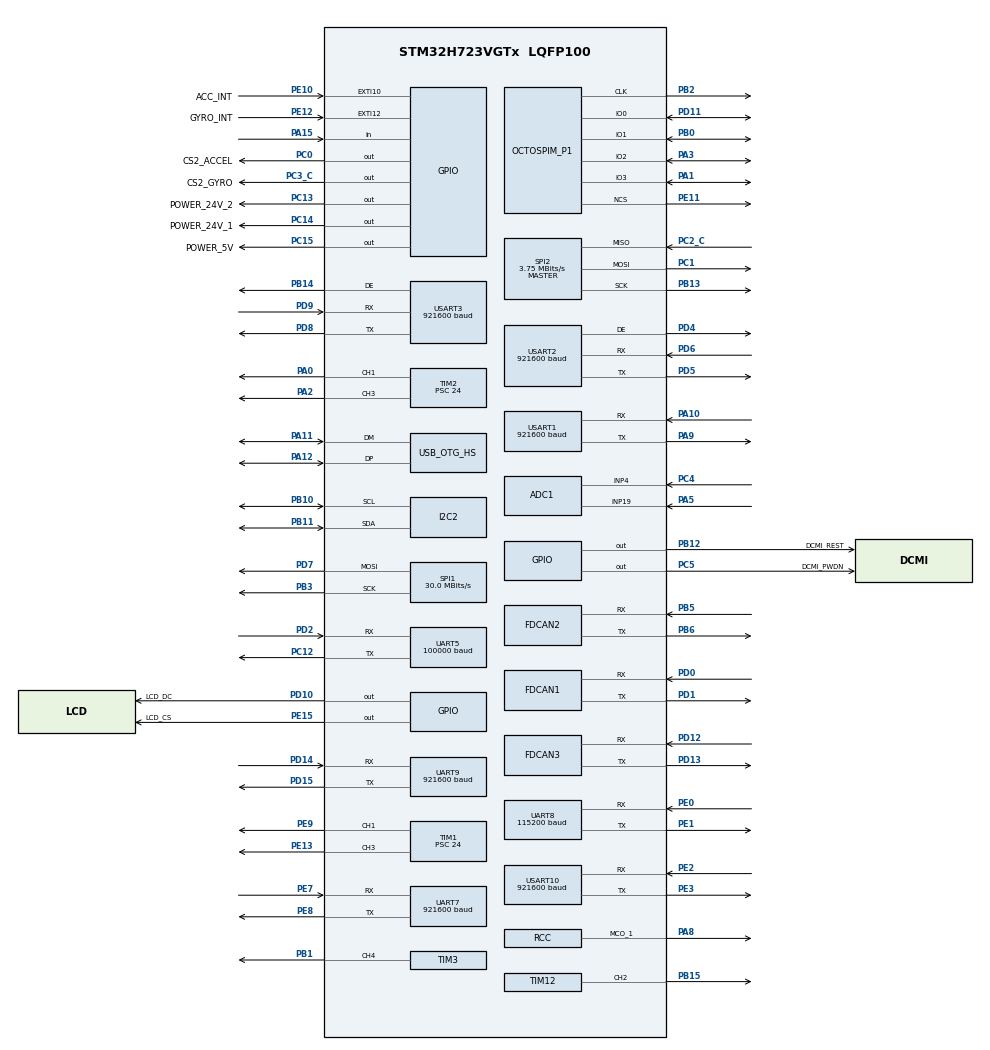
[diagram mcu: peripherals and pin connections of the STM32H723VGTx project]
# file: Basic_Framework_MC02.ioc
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ADC1.Channel-0\#ChannelRegularConversion=ADC_CHANNEL_4
ADC1.Channel-1\#ChannelRegularConversion=ADC_CHANNEL_19
ADC1.ClockPrescaler=ADC_CLOCK_ASYNC_DIV64
ADC1.ContinuousConvMode=ENABLE
ADC1.ConversionDataManagement=ADC_CONVERSIONDATA_DMA_CIRCULAR
ADC1.NbrOfConversion=2
ADC1.NbrOfConversionFlag=1
ADC1.OffsetNumber-0\#ChannelRegularConversion=ADC_OFFSET_NONE
ADC1.OffsetNumber-1\#ChannelRegularConversion=ADC_OFFSET_NONE
ADC1.OffsetSignedSaturation-0\#ChannelRegularConversion=DISABLE
ADC1.OffsetSignedSaturation-1\#ChannelRegularConversion=DISABLE
ADC1.Rank-0\#ChannelRegularConversion=1
ADC1.Rank-1\#ChannelRegularConversion=2
ADC1.SamplingTime-0\#ChannelRegularConversion=ADC_SAMPLETIME_32CYCLES_5
ADC1.SamplingTime-1\#ChannelRegularConversion=ADC_SAMPLETIME_32CYCLES_5
ADC1.master=1
CORTEX_M7.BaseAddress-Cortex_Memory_Protection_Unit_Region0_Settings=0x24000000
CORTEX_M7.CPU_DCache=Disabled
CORTEX_M7.CPU_ICache=Disabled
CORTEX_M7.Enable-Cortex_Memory_Protection_Unit_Region0_Settings=MPU_REGION_ENABLE
CORTEX_M7.IsBufferable-Cortex_Memory_Protection_Unit_Region0_Settings=MPU_ACCESS_BUFFERABLE
CORTEX_M7.IsCacheable-Cortex_Memory_Protection_Unit_Region0_Settings=MPU_ACCESS_CACHEABLE
CORTEX_M7.MPU_Control=__NULL
CORTEX_M7.Size-Cortex_Memory_Protection_Unit_Region0_Settings=MPU_REGION_SIZE_512B
CORTEX_M7.TypeExtField-Cortex_Memory_Protection_Unit_Region0_Settings=MPU_TEX_LEVEL1
Dma.ADC1.0.Direction=DMA_PERIPH_TO_MEMORY
Dma.ADC1.0.EventEnable=DISABLE
Dma.ADC1.0.FIFOMode=DMA_FIFOMODE_DISABLE
Dma.ADC1.0.Instance=DMA1_Stream0
Dma.ADC1.0.MemDataAlignment=DMA_MDATAALIGN_HALFWORD
Dma.ADC1.0.MemInc=DMA_MINC_ENABLE
Dma.ADC1.0.Mode=DMA_CIRCULAR
Dma.ADC1.0.PeriphDataAlignment=DMA_PDATAALIGN_HALFWORD
Dma.ADC1.0.PeriphInc=DMA_PINC_DISABLE
Dma.ADC1.0.Polarity=HAL_DMAMUX_REQ_GEN_RISING
Dma.ADC1.0.Priority=DMA_PRIORITY_LOW
Dma.ADC1.0.RequestNumber=1
Dma.ADC1.0.SignalID=NONE
Dma.ADC1.0.SyncEnable=DISABLE
Dma.ADC1.0.SyncPolarity=HAL_DMAMUX_SYNC_NO_EVENT
Dma.ADC1.0.SyncRequestNumber=1
Dma.ADC1.0.SyncSignalID=NONE
Dma.I2C2_RX.1.Direction=DMA_PERIPH_TO_MEMORY
Dma.I2C2_RX.1.EventEnable=DISABLE
Dma.I2C2_RX.1.FIFOMode=DMA_FIFOMODE_DISABLE
Dma.I2C2_RX.1.Instance=DMA1_Stream2
Dma.I2C2_RX.1.MemDataAlignment=DMA_MDATAALIGN_BYTE
Dma.I2C2_RX.1.MemInc=DMA_MINC_ENABLE
Dma.I2C2_RX.1.Mode=DMA_NORMAL
Dma.I2C2_RX.1.PeriphDataAlignment=DMA_PDATAALIGN_BYTE
Dma.I2C2_RX.1.PeriphInc=DMA_PINC_DISABLE
Dma.I2C2_RX.1.Polarity=HAL_DMAMUX_REQ_GEN_RISING
Dma.I2C2_RX.1.Priority=DMA_PRIORITY_LOW
Dma.I2C2_RX.1.RequestNumber=1
Dma.I2C2_RX.1.SignalID=NONE
Dma.I2C2_RX.1.SyncEnable=DISABLE
Dma.I2C2_RX.1.SyncPolarity=HAL_DMAMUX_SYNC_NO_EVENT
Dma.I2C2_RX.1.SyncRequestNumber=1
Dma.I2C2_RX.1.SyncSignalID=NONE
Dma.I2C2_TX.2.Direction=DMA_MEMORY_TO_PERIPH
Dma.I2C2_TX.2.EventEnable=DISABLE
Dma.I2C2_TX.2.FIFOMode=DMA_FIFOMODE_DISABLE
Dma.I2C2_TX.2.Instance=DMA1_Stream3
Dma.I2C2_TX.2.MemDataAlignment=DMA_MDATAALIGN_BYTE
Dma.I2C2_TX.2.MemInc=DMA_MINC_ENABLE
Dma.I2C2_TX.2.Mode=DMA_NORMAL
Dma.I2C2_TX.2.PeriphDataAlignment=DMA_PDATAALIGN_BYTE
Dma.I2C2_TX.2.PeriphInc=DMA_PINC_DISABLE
Dma.I2C2_TX.2.Polarity=HAL_DMAMUX_REQ_GEN_RISING
Dma.I2C2_TX.2.Priority=DMA_PRIORITY_LOW
Dma.I2C2_TX.2.RequestNumber=1
Dma.I2C2_TX.2.SignalID=NONE
Dma.I2C2_TX.2.SyncEnable=DISABLE
Dma.I2C2_TX.2.SyncPolarity=HAL_DMAMUX_SYNC_NO_EVENT
Dma.I2C2_TX.2.SyncRequestNumber=1
Dma.I2C2_TX.2.SyncSignalID=NONE
Dma.Request0=ADC1
Dma.Request1=I2C2_RX
Dma.Request10=USART10_TX
Dma.Request11=UART7_RX
Dma.Request12=UART7_TX
Dma.Request13=UART5_RX
Dma.Request14=UART8_RX
Dma.Request15=UART8_TX
Dma.Request2=I2C2_TX
Dma.Request3=UART9_RX
Dma.Request4=UART9_TX
Dma.Request5=USART3_RX
Dma.Request6=USART3_TX
Dma.Request7=USART1_TX
Dma.Request8=USART1_RX
Dma.Request9=USART10_RX
Dma.UART5_RX.13.Direction=DMA_PERIPH_TO_MEMORY
Dma.UART5_RX.13.EventEnable=DISABLE
Dma.UART5_RX.13.FIFOMode=DMA_FIFOMODE_DISABLE
Dma.UART5_RX.13.Instance=DMA1_Stream7
Dma.UART5_RX.13.MemDataAlignment=DMA_MDATAALIGN_BYTE
Dma.UART5_RX.13.MemInc=DMA_MINC_ENABLE
Dma.UART5_RX.13.Mode=DMA_NORMAL
Dma.UART5_RX.13.PeriphDataAlignment=DMA_PDATAALIGN_BYTE
Dma.UART5_RX.13.PeriphInc=DMA_PINC_DISABLE
Dma.UART5_RX.13.Polarity=HAL_DMAMUX_REQ_GEN_RISING
Dma.UART5_RX.13.Priority=DMA_PRIORITY_VERY_HIGH
Dma.UART5_RX.13.RequestNumber=1
Dma.UART5_RX.13.SignalID=NONE
Dma.UART5_RX.13.SyncEnable=DISABLE
Dma.UART5_RX.13.SyncPolarity=HAL_DMAMUX_SYNC_NO_EVENT
Dma.UART5_RX.13.SyncRequestNumber=1
Dma.UART5_RX.13.SyncSignalID=NONE
Dma.UART7_RX.11.Direction=DMA_PERIPH_TO_MEMORY
Dma.UART7_RX.11.EventEnable=DISABLE
Dma.UART7_RX.11.FIFOMode=DMA_FIFOMODE_DISABLE
Dma.UART7_RX.11.Instance=DMA2_Stream0
Dma.UART7_RX.11.MemDataAlignment=DMA_MDATAALIGN_BYTE
Dma.UART7_RX.11.MemInc=DMA_MINC_ENABLE
Dma.UART7_RX.11.Mode=DMA_NORMAL
Dma.UART7_RX.11.PeriphDataAlignment=DMA_PDATAALIGN_BYTE
Dma.UART7_RX.11.PeriphInc=DMA_PINC_DISABLE
Dma.UART7_RX.11.Polarity=HAL_DMAMUX_REQ_GEN_RISING
Dma.UART7_RX.11.Priority=DMA_PRIORITY_LOW
Dma.UART7_RX.11.RequestNumber=1
Dma.UART7_RX.11.SignalID=NONE
Dma.UART7_RX.11.SyncEnable=DISABLE
Dma.UART7_RX.11.SyncPolarity=HAL_DMAMUX_SYNC_NO_EVENT
Dma.UART7_RX.11.SyncRequestNumber=1
Dma.UART7_RX.11.SyncSignalID=NONE
Dma.UART7_TX.12.Direction=DMA_MEMORY_TO_PERIPH
Dma.UART7_TX.12.EventEnable=DISABLE
Dma.UART7_TX.12.FIFOMode=DMA_FIFOMODE_DISABLE
Dma.UART7_TX.12.Instance=DMA2_Stream1
Dma.UART7_TX.12.MemDataAlignment=DMA_MDATAALIGN_BYTE
Dma.UART7_TX.12.MemInc=DMA_MINC_ENABLE
Dma.UART7_TX.12.Mode=DMA_NORMAL
Dma.UART7_TX.12.PeriphDataAlignment=DMA_PDATAALIGN_BYTE
Dma.UART7_TX.12.PeriphInc=DMA_PINC_DISABLE
Dma.UART7_TX.12.Polarity=HAL_DMAMUX_REQ_GEN_RISING
Dma.UART7_TX.12.Priority=DMA_PRIORITY_LOW
Dma.UART7_TX.12.RequestNumber=1
Dma.UART7_TX.12.SignalID=NONE
Dma.UART7_TX.12.SyncEnable=DISABLE
Dma.UART7_TX.12.SyncPolarity=HAL_DMAMUX_SYNC_NO_EVENT
Dma.UART7_TX.12.SyncRequestNumber=1
Dma.UART7_TX.12.SyncSignalID=NONE
Dma.UART8_RX.14.Direction=DMA_PERIPH_TO_MEMORY
Dma.UART8_RX.14.EventEnable=DISABLE
Dma.UART8_RX.14.FIFOMode=DMA_FIFOMODE_DISABLE
Dma.UART8_RX.14.Instance=DMA2_Stream6
Dma.UART8_RX.14.MemDataAlignment=DMA_MDATAALIGN_BYTE
Dma.UART8_RX.14.MemInc=DMA_MINC_ENABLE
Dma.UART8_RX.14.Mode=DMA_NORMAL
Dma.UART8_RX.14.PeriphDataAlignment=DMA_PDATAALIGN_BYTE
Dma.UART8_RX.14.PeriphInc=DMA_PINC_DISABLE
Dma.UART8_RX.14.Polarity=HAL_DMAMUX_REQ_GEN_RISING
Dma.UART8_RX.14.Priority=DMA_PRIORITY_LOW
Dma.UART8_RX.14.RequestNumber=1
Dma.UART8_RX.14.SignalID=NONE
Dma.UART8_RX.14.SyncEnable=DISABLE
Dma.UART8_RX.14.SyncPolarity=HAL_DMAMUX_SYNC_NO_EVENT
Dma.UART8_RX.14.SyncRequestNumber=1
Dma.UART8_RX.14.SyncSignalID=NONE
Dma.UART8_TX.15.Direction=DMA_MEMORY_TO_PERIPH
Dma.UART8_TX.15.EventEnable=DISABLE
Dma.UART8_TX.15.FIFOMode=DMA_FIFOMODE_DISABLE
Dma.UART8_TX.15.Instance=DMA2_Stream7
Dma.UART8_TX.15.MemDataAlignment=DMA_MDATAALIGN_BYTE
Dma.UART8_TX.15.MemInc=DMA_MINC_ENABLE
Dma.UART8_TX.15.Mode=DMA_NORMAL
Dma.UART8_TX.15.PeriphDataAlignment=DMA_PDATAALIGN_BYTE
Dma.UART8_TX.15.PeriphInc=DMA_PINC_DISABLE
Dma.UART8_TX.15.Polarity=HAL_DMAMUX_REQ_GEN_RISING
Dma.UART8_TX.15.Priority=DMA_PRIORITY_LOW
Dma.UART8_TX.15.RequestNumber=1
Dma.UART8_TX.15.SignalID=NONE
Dma.UART8_TX.15.SyncEnable=DISABLE
Dma.UART8_TX.15.SyncPolarity=HAL_DMAMUX_SYNC_NO_EVENT
Dma.UART8_TX.15.SyncRequestNumber=1
Dma.UART8_TX.15.SyncSignalID=NONE
Dma.UART9_RX.3.Direction=DMA_PERIPH_TO_MEMORY
Dma.UART9_RX.3.EventEnable=DISABLE
Dma.UART9_RX.3.FIFOMode=DMA_FIFOMODE_DISABLE
Dma.UART9_RX.3.Instance=DMA1_Stream4
Dma.UART9_RX.3.MemDataAlignment=DMA_MDATAALIGN_BYTE
Dma.UART9_RX.3.MemInc=DMA_MINC_ENABLE
Dma.UART9_RX.3.Mode=DMA_NORMAL
Dma.UART9_RX.3.PeriphDataAlignment=DMA_PDATAALIGN_BYTE
Dma.UART9_RX.3.PeriphInc=DMA_PINC_DISABLE
Dma.UART9_RX.3.Polarity=HAL_DMAMUX_REQ_GEN_RISING
Dma.UART9_RX.3.Priority=DMA_PRIORITY_HIGH
Dma.UART9_RX.3.RequestNumber=1
Dma.UART9_RX.3.SignalID=NONE
Dma.UART9_RX.3.SyncEnable=DISABLE
Dma.UART9_RX.3.SyncPolarity=HAL_DMAMUX_SYNC_NO_EVENT
Dma.UART9_RX.3.SyncRequestNumber=1
Dma.UART9_RX.3.SyncSignalID=NONE
Dma.UART9_TX.4.Direction=DMA_MEMORY_TO_PERIPH
Dma.UART9_TX.4.EventEnable=DISABLE
Dma.UART9_TX.4.FIFOMode=DMA_FIFOMODE_DISABLE
Dma.UART9_TX.4.Instance=DMA1_Stream5
Dma.UART9_TX.4.MemDataAlignment=DMA_MDATAALIGN_BYTE
Dma.UART9_TX.4.MemInc=DMA_MINC_ENABLE
Dma.UART9_TX.4.Mode=DMA_NORMAL
Dma.UART9_TX.4.PeriphDataAlignment=DMA_PDATAALIGN_BYTE
Dma.UART9_TX.4.PeriphInc=DMA_PINC_DISABLE
Dma.UART9_TX.4.Polarity=HAL_DMAMUX_REQ_GEN_RISING
Dma.UART9_TX.4.Priority=DMA_PRIORITY_HIGH
Dma.UART9_TX.4.RequestNumber=1
Dma.UART9_TX.4.SignalID=NONE
Dma.UART9_TX.4.SyncEnable=DISABLE
Dma.UART9_TX.4.SyncPolarity=HAL_DMAMUX_SYNC_NO_EVENT
Dma.UART9_TX.4.SyncRequestNumber=1
Dma.UART9_TX.4.SyncSignalID=NONE
Dma.USART10_RX.9.Direction=DMA_PERIPH_TO_MEMORY
Dma.USART10_RX.9.EventEnable=DISABLE
Dma.USART10_RX.9.FIFOMode=DMA_FIFOMODE_DISABLE
Dma.USART10_RX.9.Instance=DMA2_Stream4
Dma.USART10_RX.9.MemDataAlignment=DMA_MDATAALIGN_BYTE
Dma.USART10_RX.9.MemInc=DMA_MINC_ENABLE
Dma.USART10_RX.9.Mode=DMA_NORMAL
Dma.USART10_RX.9.PeriphDataAlignment=DMA_PDATAALIGN_BYTE
Dma.USART10_RX.9.PeriphInc=DMA_PINC_DISABLE
Dma.USART10_RX.9.Polarity=HAL_DMAMUX_REQ_GEN_RISING
Dma.USART10_RX.9.Priority=DMA_PRIORITY_LOW
Dma.USART10_RX.9.RequestNumber=1
Dma.USART10_RX.9.SignalID=NONE
Dma.USART10_RX.9.SyncEnable=DISABLE
Dma.USART10_RX.9.SyncPolarity=HAL_DMAMUX_SYNC_NO_EVENT
Dma.USART10_RX.9.SyncRequestNumber=1
Dma.USART10_RX.9.SyncSignalID=NONE
Dma.USART10_TX.10.Direction=DMA_MEMORY_TO_PERIPH
Dma.USART10_TX.10.EventEnable=DISABLE
Dma.USART10_TX.10.FIFOMode=DMA_FIFOMODE_DISABLE
Dma.USART10_TX.10.Instance=DMA2_Stream5
Dma.USART10_TX.10.MemDataAlignment=DMA_MDATAALIGN_BYTE
Dma.USART10_TX.10.MemInc=DMA_MINC_ENABLE
Dma.USART10_TX.10.Mode=DMA_NORMAL
Dma.USART10_TX.10.PeriphDataAlignment=DMA_PDATAALIGN_BYTE
Dma.USART10_TX.10.PeriphInc=DMA_PINC_DISABLE
Dma.USART10_TX.10.Polarity=HAL_DMAMUX_REQ_GEN_RISING
Dma.USART10_TX.10.Priority=DMA_PRIORITY_LOW
Dma.USART10_TX.10.RequestNumber=1
Dma.USART10_TX.10.SignalID=NONE
Dma.USART10_TX.10.SyncEnable=DISABLE
Dma.USART10_TX.10.SyncPolarity=HAL_DMAMUX_SYNC_NO_EVENT
Dma.USART10_TX.10.SyncRequestNumber=1
Dma.USART10_TX.10.SyncSignalID=NONE
Dma.USART1_RX.8.Direction=DMA_PERIPH_TO_MEMORY
Dma.USART1_RX.8.EventEnable=DISABLE
Dma.USART1_RX.8.FIFOMode=DMA_FIFOMODE_DISABLE
Dma.USART1_RX.8.Instance=DMA2_Stream3
Dma.USART1_RX.8.MemDataAlignment=DMA_MDATAALIGN_BYTE
Dma.USART1_RX.8.MemInc=DMA_MINC_ENABLE
Dma.USART1_RX.8.Mode=DMA_NORMAL
Dma.USART1_RX.8.PeriphDataAlignment=DMA_PDATAALIGN_BYTE
Dma.USART1_RX.8.PeriphInc=DMA_PINC_DISABLE
Dma.USART1_RX.8.Polarity=HAL_DMAMUX_REQ_GEN_RISING
Dma.USART1_RX.8.Priority=DMA_PRIORITY_LOW
Dma.USART1_RX.8.RequestNumber=1
Dma.USART1_RX.8.SignalID=NONE
Dma.USART1_RX.8.SyncEnable=DISABLE
Dma.USART1_RX.8.SyncPolarity=HAL_DMAMUX_SYNC_NO_EVENT
Dma.USART1_RX.8.SyncRequestNumber=1
Dma.USART1_RX.8.SyncSignalID=NONE
Dma.USART1_TX.7.Direction=DMA_MEMORY_TO_PERIPH
Dma.USART1_TX.7.EventEnable=DISABLE
Dma.USART1_TX.7.FIFOMode=DMA_FIFOMODE_DISABLE
Dma.USART1_TX.7.Instance=DMA2_Stream2
Dma.USART1_TX.7.MemDataAlignment=DMA_MDATAALIGN_BYTE
Dma.USART1_TX.7.MemInc=DMA_MINC_ENABLE
Dma.USART1_TX.7.Mode=DMA_NORMAL
Dma.USART1_TX.7.PeriphDataAlignment=DMA_PDATAALIGN_BYTE
Dma.USART1_TX.7.PeriphInc=DMA_PINC_DISABLE
Dma.USART1_TX.7.Polarity=HAL_DMAMUX_REQ_GEN_RISING
Dma.USART1_TX.7.Priority=DMA_PRIORITY_LOW
Dma.USART1_TX.7.RequestNumber=1
Dma.USART1_TX.7.SignalID=NONE
Dma.USART1_TX.7.SyncEnable=DISABLE
Dma.USART1_TX.7.SyncPolarity=HAL_DMAMUX_SYNC_NO_EVENT
Dma.USART1_TX.7.SyncRequestNumber=1
Dma.USART1_TX.7.SyncSignalID=NONE
Dma.USART3_RX.5.Direction=DMA_PERIPH_TO_MEMORY
Dma.USART3_RX.5.EventEnable=DISABLE
Dma.USART3_RX.5.FIFOMode=DMA_FIFOMODE_DISABLE
Dma.USART3_RX.5.Instance=DMA1_Stream6
Dma.USART3_RX.5.MemDataAlignment=DMA_MDATAALIGN_BYTE
Dma.USART3_RX.5.MemInc=DMA_MINC_ENABLE
Dma.USART3_RX.5.Mode=DMA_NORMAL
Dma.USART3_RX.5.PeriphDataAlignment=DMA_PDATAALIGN_BYTE
Dma.USART3_RX.5.PeriphInc=DMA_PINC_DISABLE
Dma.USART3_RX.5.Polarity=HAL_DMAMUX_REQ_GEN_RISING
Dma.USART3_RX.5.Priority=DMA_PRIORITY_LOW
Dma.USART3_RX.5.RequestNumber=1
Dma.USART3_RX.5.SignalID=NONE
Dma.USART3_RX.5.SyncEnable=DISABLE
Dma.USART3_RX.5.SyncPolarity=HAL_DMAMUX_SYNC_NO_EVENT
Dma.USART3_RX.5.SyncRequestNumber=1
Dma.USART3_RX.5.SyncSignalID=NONE
Dma.USART3_TX.6.Direction=DMA_MEMORY_TO_PERIPH
Dma.USART3_TX.6.EventEnable=DISABLE
Dma.USART3_TX.6.FIFOMode=DMA_FIFOMODE_DISABLE
Dma.USART3_TX.6.Instance=DMA1_Stream1
Dma.USART3_TX.6.MemDataAlignment=DMA_MDATAALIGN_BYTE
Dma.USART3_TX.6.MemInc=DMA_MINC_ENABLE
Dma.USART3_TX.6.Mode=DMA_NORMAL
Dma.USART3_TX.6.PeriphDataAlignment=DMA_PDATAALIGN_BYTE
Dma.USART3_TX.6.PeriphInc=DMA_PINC_DISABLE
Dma.USART3_TX.6.Polarity=HAL_DMAMUX_REQ_GEN_RISING
Dma.USART3_TX.6.Priority=DMA_PRIORITY_LOW
Dma.USART3_TX.6.RequestNumber=1
Dma.USART3_TX.6.SignalID=NONE
Dma.USART3_TX.6.SyncEnable=DISABLE
Dma.USART3_TX.6.SyncPolarity=HAL_DMAMUX_SYNC_NO_EVENT
Dma.USART3_TX.6.SyncRequestNumber=1
Dma.USART3_TX.6.SyncSignalID=NONE
FDCAN1.CalculateBaudRateNominal=1000000
FDCAN1.CalculateTimeBitNominal=1000
FDCAN1.CalculateTimeQuantumNominal=25.0
FDCAN1.DataPrescaler=3
FDCAN1.DataSyncJumpWidth=10
FDCAN1.DataTimeSeg1=29
FDCAN1.DataTimeSeg2=10
FDCAN1.NominalPrescaler=3
FDCAN1.NominalTimeSeg1=29
FDCAN1.NominalTimeSeg2=10
FDCAN1.ProtocolException=ENABLE
FDCAN1.RxFifo0ElmtsNbr=4
FDCAN1.RxFifo1ElmtsNbr=4
FDCAN1.StdFiltersNbr=14
FDCAN1.TxFifoQueueElmtsNbr=4
FDCAN2.CalculateBaudRateNominal=1000000
FDCAN2.CalculateTimeBitNominal=1000
FDCAN2.CalculateTimeQuantumNominal=25.0
FDCAN2.DataPrescaler=3
FDCAN2.DataSyncJumpWidth=10
FDCAN2.DataTimeSeg1=29
FDCAN2.DataTimeSeg2=10
FDCAN2.MessageRAMOffset=0x406
FDCAN2.NominalPrescaler=3
FDCAN2.NominalTimeSeg1=29
FDCAN2.NominalTimeSeg2=10
FDCAN2.RxFifo0ElmtsNbr=4
FDCAN2.RxFifo1ElmtsNbr=4
FDCAN2.StdFiltersNbr=14
FDCAN2.TxFifoQueueElmtsNbr=4
FDCAN3.CalculateBaudRateNominal=1000000
FDCAN3.CalculateTimeBitNominal=1000
FDCAN3.CalculateTimeQuantumNominal=25.0
FDCAN3.DataPrescaler=3
FDCAN3.DataSyncJumpWidth=10
FDCAN3.DataTimeSeg1=29
FDCAN3.DataTimeSeg2=10
FDCAN3.MessageRAMOffset=0x812
FDCAN3.NominalPrescaler=3
FDCAN3.NominalTimeSeg1=29
FDCAN3.NominalTimeSeg2=10
FDCAN3.RxFifo0ElmtsNbr=4
FDCAN3.RxFifo1ElmtsNbr=4
FDCAN3.StdFiltersNbr=14
FDCAN3.TxFifoQueueElmtsNbr=4
FREERTOS.INCLUDE_eTaskGetState=0
FREERTOS.INCLUDE_uxTaskGetStackHighWaterMark=0
FREERTOS.INCLUDE_vTaskDelayUntil=1
FREERTOS.INCLUDE_xQueueGetMutexHolder=1
FREERTOS.INCLUDE_xTaskGetCurrentTaskHandle=0
FREERTOS.INCLUDE_xTimerPendFunctionCall=0
FREERTOS.Tasks01=defaultTask,0,128,StartDefaultTask,Default,NULL,Dynamic,NULL,NULL
FREERTOS.configENABLE_FPU=1
FREERTOS.configGENERATE_RUN_TIME_STATS=1
FREERTOS.configTOTAL_HEAP_SIZE=25600
FREERTOS.configUSE_COUNTING_SEMAPHORES=1
FREERTOS.configUSE_RECURSIVE_MUTEXES=0
FREERTOS.configUSE_TIMERS=1
FREERTOS.configUSE_TRACE_FACILITY=1
I2C2.Timing=0x307075B1
Mcu.Family=STM32H7
Mcu.Name=STM32H723VGTx
Mcu.Package=LQFP100
NVIC.DMA1_Stream0_IRQn=true\:5\:0\:false\:false\:true\:false\:false\:true\:true
NVIC.DMA1_Stream1_IRQn=true\:5\:0\:false\:false\:true\:true\:false\:true\:true
NVIC.DMA1_Stream2_IRQn=true\:5\:0\:false\:false\:true\:true\:false\:true\:true
NVIC.DMA1_Stream3_IRQn=true\:5\:0\:false\:false\:true\:true\:false\:true\:true
NVIC.DMA1_Stream4_IRQn=true\:5\:0\:false\:false\:true\:true\:false\:true\:true
NVIC.DMA1_Stream5_IRQn=true\:5\:0\:false\:false\:true\:true\:false\:true\:true
NVIC.DMA1_Stream6_IRQn=true\:5\:0\:false\:false\:true\:true\:false\:true\:true
NVIC.DMA1_Stream7_IRQn=true\:5\:0\:false\:false\:true\:true\:false\:true\:true
NVIC.DMA2_Stream0_IRQn=true\:5\:0\:false\:false\:true\:true\:false\:true\:true
NVIC.DMA2_Stream1_IRQn=true\:5\:0\:false\:false\:true\:true\:false\:true\:true
NVIC.DMA2_Stream2_IRQn=true\:5\:0\:false\:false\:true\:true\:false\:true\:true
NVIC.DMA2_Stream3_IRQn=true\:5\:0\:false\:false\:true\:true\:false\:true\:true
NVIC.DMA2_Stream4_IRQn=true\:5\:0\:false\:false\:true\:true\:false\:true\:true
NVIC.DMA2_Stream5_IRQn=true\:5\:0\:false\:false\:true\:true\:false\:true\:true
NVIC.DMA2_Stream6_IRQn=true\:5\:0\:false\:false\:true\:true\:false\:true\:true
NVIC.DMA2_Stream7_IRQn=true\:5\:0\:false\:false\:true\:true\:false\:true\:true
NVIC.FDCAN1_IT0_IRQn=true\:5\:0\:false\:false\:true\:true\:true\:true\:true
NVIC.FDCAN1_IT1_IRQn=true\:5\:0\:false\:false\:true\:true\:true\:true\:true
NVIC.FDCAN2_IT0_IRQn=true\:5\:0\:false\:false\:true\:true\:true\:true\:true
NVIC.FDCAN2_IT1_IRQn=true\:5\:0\:false\:false\:true\:true\:true\:true\:true
NVIC.FDCAN3_IT0_IRQn=true\:5\:0\:false\:false\:true\:true\:true\:true\:true
NVIC.FDCAN3_IT1_IRQn=true\:5\:0\:false\:false\:true\:true\:true\:true\:true
NVIC.I2C2_EV_IRQn=true\:5\:0\:false\:false\:true\:true\:true\:true\:true
NVIC.OTG_HS_IRQn=true\:5\:0\:false\:false\:true\:true\:false\:true\:true
NVIC.PriorityGroup=NVIC_PRIORITYGROUP_4
NVIC.TIM23_IRQn=true\:15\:0\:false\:false\:true\:false\:false\:true\:true
NVIC.TimeBase=TIM23_IRQn
NVIC.TimeBaseIP=TIM23
NVIC.UART5_IRQn=true\:5\:0\:false\:false\:true\:true\:true\:true\:true
NVIC.UART7_IRQn=true\:5\:0\:true\:false\:true\:false\:true\:true\:true
NVIC.UART8_IRQn=true\:5\:0\:false\:false\:true\:true\:true\:true\:true
NVIC.UART9_IRQn=true\:5\:0\:false\:false\:true\:true\:true\:true\:true
NVIC.USART10_IRQn=true\:5\:0\:true\:false\:true\:false\:true\:true\:true
NVIC.USART1_IRQn=true\:5\:0\:true\:false\:true\:false\:true\:true\:true
NVIC.USART2_IRQn=true\:5\:0\:true\:false\:true\:false\:true\:true\:true
NVIC.USART3_IRQn=true\:5\:0\:true\:false\:true\:false\:true\:true\:true
OCTOSPI2.ClockMode=HAL_OSPI_CLOCK_MODE_3
OCTOSPI2.ClockPrescaler=3
OCTOSPI2.DeviceSize=23
OCTOSPI2.DeviceType=SPI_DEVICE_FLASH
OCTOSPI2.FifoThreshold=8
OCTOSPI2.SampleShifting=HAL_OSPI_SAMPLE_SHIFTING_HALFCYCLE
PA0.Signal=S_TIM2_CH1_ETR
PA1.Mode=OCTOSPI2_IOL_Port1L
PA1.Signal=OCTOSPIM_P1_IO3
PA10.Mode=Asynchronous
PA10.Signal=USART1_RX
PA11.Mode=Device_Only_FS
PA11.Signal=USB_OTG_HS_DM
PA12.Mode=Device_Only_FS
PA12.Signal=USB_OTG_HS_DP
PA13(JTMS/SWDIO).Mode=Serial_Wire
PA13(JTMS/SWDIO).Signal=DEBUG_JTMS-SWDIO
PA14(JTCK/SWCLK).Mode=Serial_Wire
PA14(JTCK/SWCLK).Signal=DEBUG_JTCK-SWCLK
PA15(JTDI).Signal=GPIO_Input
PA2.Signal=S_TIM2_CH3
PA3.Mode=OCTOSPI2_IOL_Port1L
PA3.Signal=OCTOSPIM_P1_IO2
PA5.Signal=ADCx_INP19
PA8.Mode=Clock-out-1
PA8.Signal=RCC_MCO_1
PA9.Mode=Asynchronous
PA9.Signal=USART1_TX
PB0.Mode=OCTOSPI2_IOL_Port1L
PB0.Signal=OCTOSPIM_P1_IO1
PB1.Signal=S_TIM3_CH4
PB10.Mode=I2C
PB10.Signal=I2C2_SCL
PB11.Mode=I2C
PB11.Signal=I2C2_SDA
PB12.GPIO_Label=DCMI_REST
PB12.GPIO_PuPd=GPIO_PULLUP
PB12.GPIO_Speed=GPIO_SPEED_FREQ_VERY_HIGH
PB12.PinState=GPIO_PIN_SET
PB12.Signal=GPIO_Output
PB13.GPIO_Speed=GPIO_SPEED_FREQ_VERY_HIGH
PB13.Mode=Full_Duplex_Master
PB13.Signal=SPI2_SCK
PB14.Mode=Hardware Flow Control (RS485)
PB14.Signal=USART3_DE
PB15.Signal=S_TIM12_CH2
PB2.Mode=O2_P1_CLK
PB2.Signal=OCTOSPIM_P1_CLK
PB3(JTDO/TRACESWO).GPIO_Speed=GPIO_SPEED_FREQ_VERY_HIGH
PB3(JTDO/TRACESWO).Mode=TX_Only_Simplex_Unidirect_Master
PB3(JTDO/TRACESWO).Signal=SPI1_SCK
PB5.Mode=FDCAN_Activate
PB5.Signal=FDCAN2_RX
PB6.Mode=FDCAN_Activate
PB6.Signal=FDCAN2_TX
PC0.GPIO_Label=CS2_ACCEL
PC0.GPIO_Speed=GPIO_SPEED_FREQ_VERY_HIGH
PC0.PinState=GPIO_PIN_SET
PC0.Signal=GPIO_Output
PC1.GPIO_Speed=GPIO_SPEED_FREQ_VERY_HIGH
PC1.Mode=Full_Duplex_Master
PC1.Signal=SPI2_MOSI
PC12.Mode=Asynchronous
PC12.Signal=UART5_TX
PC13.GPIO_Label=POWER_24V_2
PC13.PinState=GPIO_PIN_SET
PC13.Signal=GPIO_Output
PC14-OSC32_IN.GPIO_Label=POWER_24V_1
PC14-OSC32_IN.PinState=GPIO_PIN_SET
PC14-OSC32_IN.Signal=GPIO_Output
PC15-OSC32_OUT.GPIO_Label=POWER_5V
PC15-OSC32_OUT.PinState=GPIO_PIN_SET
PC15-OSC32_OUT.Signal=GPIO_Output
PC2_C.GPIO_Speed=GPIO_SPEED_FREQ_VERY_HIGH
PC2_C.Mode=Full_Duplex_Master
PC2_C.Signal=SPI2_MISO
PC3_C.GPIO_Label=CS2_GYRO
PC3_C.GPIO_Speed=GPIO_SPEED_FREQ_VERY_HIGH
PC3_C.PinState=GPIO_PIN_SET
PC3_C.Signal=GPIO_Output
PC4.Signal=ADCx_INP4
PC5.GPIO_Label=DCMI_PWDN
PC5.GPIO_PuPd=GPIO_NOPULL
PC5.GPIO_Speed=GPIO_SPEED_FREQ_VERY_HIGH
PC5.PinState=GPIO_PIN_SET
PC5.Signal=GPIO_Output
PD0.Mode=FDCAN_Activate
PD0.Signal=FDCAN1_RX
PD1.Mode=FDCAN_Activate
PD1.Signal=FDCAN1_TX
PD10.GPIO_Label=LCD_DC
PD10.Signal=GPIO_Output
PD11.Mode=OCTOSPI2_IOL_Port1L
PD11.Signal=OCTOSPIM_P1_IO0
PD12.Mode=FDCAN_Activate
PD12.Signal=FDCAN3_RX
PD13.Mode=FDCAN_Activate
PD13.Signal=FDCAN3_TX
PD14.Mode=Asynchronous
PD14.Signal=UART9_RX
PD15.Mode=Asynchronous
PD15.Signal=UART9_TX
PD2.Mode=Asynchronous
PD2.Signal=UART5_RX
PD4.Mode=Hardware Flow Control (RS485)
PD4.Signal=USART2_DE
PD5.Mode=Asynchronous
PD5.Signal=USART2_TX
PD6.Mode=Asynchronous
PD6.Signal=USART2_RX
PD7.GPIO_Speed=GPIO_SPEED_FREQ_VERY_HIGH
PD7.Mode=TX_Only_Simplex_Unidirect_Master
PD7.Signal=SPI1_MOSI
PD8.Mode=Asynchronous
PD8.Signal=USART3_TX
PD9.Mode=Asynchronous
PD9.Signal=USART3_RX
PE0.Mode=Asynchronous
PE0.Signal=UART8_RX
PE1.Mode=Asynchronous
PE1.Signal=UART8_TX
PE10.GPIO_Label=ACC_INT
PE10.Signal=GPXTI10
PE11.Mode=OCTOSPI2_Port1_NCS
PE11.Signal=OCTOSPIM_P1_NCS
PE12.GPIO_Label=GYRO_INT
PE12.Signal=GPXTI12
PE13.Signal=S_TIM1_CH3
PE15.GPIO_Label=LCD_CS
PE15.Signal=GPIO_Output
PE2.Mode=Asynchronous
PE2.Signal=USART10_RX
PE3.Mode=Asynchronous
PE3.Signal=USART10_TX
PE7.Mode=Asynchronous
PE7.Signal=UART7_RX
PE8.Mode=Asynchronous
PE8.Signal=UART7_TX
PE9.Signal=S_TIM1_CH1
PH0-OSC_IN.Mode=HSE-External-Oscillator
PH0-OSC_IN.Signal=RCC_OSC_IN
PH1-OSC_OUT.Mode=HSE-External-Oscillator
PH1-OSC_OUT.Signal=RCC_OSC_OUT
ProjectManager.HeapSize=0x5000
ProjectManager.StackSize=0x5000
ProjectManager.TargetToolchain=Makefile
RCC.ADCFreq_Value=96000000
RCC.APB1Freq_Value=120000000
RCC.APB2Freq_Value=120000000
RCC.APB3Freq_Value=120000000
RCC.APB4Freq_Value=120000000
RCC.CortexFreq_Value=480000000
RCC.D1PPRE=RCC_APB3_DIV2
RCC.D2PPRE1=RCC_APB1_DIV2
RCC.D2PPRE2=RCC_APB2_DIV2
RCC.D3PPRE=RCC_APB4_DIV2
RCC.DIVM1=2
RCC.DIVM2=2
RCC.DIVN1=40
RCC.DIVN2=16
RCC.DIVP1=1
RCC.DIVQ1=4
RCC.EnbaleCSS=false
RCC.HCLKFreq_Value=240000000
RCC.HPRE=RCC_HCLK_DIV2
RCC.HSE_VALUE=24000000
RCC.PLL2FRACN=0
RCC.PLL2_VCI_Range-AdvancedSettings=RCC_PLL2VCIRANGE_0
RCC.PLL2_VCO_SEL-AdvancedSettings=RCC_PLL2VCOWIDE
RCC.PLL3FRACN=0
RCC.PLL3_VCO_SEL-AdvancedSettings=RCC_PLL3VCOMEDIUM
RCC.PLLFRACN=0
RCC.PLLSourceVirtual=RCC_PLLSOURCE_HSE
RCC.SPI6CLockSelection=RCC_SPI6CLKSOURCE_HSE
RCC.SYSCLKFreq_VALUE=480000000
RCC.SYSCLKSource=RCC_SYSCLKSOURCE_PLLCLK
RCC.USBCLockSelection=RCC_USBCLKSOURCE_HSI48
RCC.USBFreq_Value=48000000
SH.ADCx_INP19.0=ADC1_INP19,IN19-Single-Ended
SH.ADCx_INP4.0=ADC1_INP4,IN4-Single-Ended
SH.S_TIM12_CH2.0=TIM12_CH2,PWM Generation2 CH2
SH.S_TIM1_CH1.0=TIM1_CH1,PWM Generation1 CH1
SH.S_TIM1_CH3.0=TIM1_CH3,PWM Generation3 CH3
SH.S_TIM2_CH1_ETR.0=TIM2_CH1,PWM Generation1 CH1
SH.S_TIM2_CH3.0=TIM2_CH3,PWM Generation3 CH3
SH.S_TIM3_CH4.0=TIM3_CH4,PWM Generation4 CH4
SPI1.BaudRatePrescaler=SPI_BAUDRATEPRESCALER_4
SPI1.CLKPolarity=SPI_POLARITY_HIGH
SPI1.CalculateBaudRate=30.0 MBits/s
SPI1.DataSize=SPI_DATASIZE_8BIT
SPI1.Direction=SPI_DIRECTION_2LINES_TXONLY
SPI1.Mode=SPI_MODE_MASTER
SPI1.VirtualType=VM_MASTER
SPI2.BaudRatePrescaler=SPI_BAUDRATEPRESCALER_32
SPI2.CLKPhase=SPI_PHASE_2EDGE
SPI2.CLKPolarity=SPI_POLARITY_HIGH
SPI2.CalculateBaudRate=3.75 MBits/s
SPI2.DataSize=SPI_DATASIZE_8BIT
SPI2.Direction=SPI_DIRECTION_2LINES
SPI2.Mode=SPI_MODE_MASTER
SPI2.VirtualType=VM_MASTER
STMicroelectronics.X-CUBE-ALGOBUILD.1.4.0.LibraryCcDSPOoLibraryJjDSPOoLibrary=true
TIM1.Channel-PWM\ Generation1\ CH1=TIM_CHANNEL_1
TIM1.Channel-PWM\ Generation3\ CH3=TIM_CHANNEL_3
TIM1.Period=10000
TIM1.Prescaler=24
TIM1.Pulse-PWM\ Generation1\ CH1=5000
TIM1.Pulse-PWM\ Generation3\ CH3=5000
TIM12.Channel-PWM\ Generation2\ CH2=TIM_CHANNEL_2
TIM12.Period=2000-1
TIM12.Prescaler=24-1
TIM2.Channel-PWM\ Generation1\ CH1=TIM_CHANNEL_1
TIM2.Channel-PWM\ Generation3\ CH3=TIM_CHANNEL_3
TIM2.Period=10000
TIM2.Prescaler=24
TIM2.Pulse-PWM\ Generation1\ CH1=5000
TIM2.Pulse-PWM\ Generation3\ CH3=5000
TIM3.AutoReloadPreload=TIM_AUTORELOAD_PRELOAD_ENABLE
TIM3.Channel-PWM\ Generation4\ CH4=TIM_CHANNEL_4
TIM3.OCPolarity_4=TIM_OCPOLARITY_HIGH
TIM3.Period=10000-1
TIM3.Prescaler=24-1
UART5.BaudRate=100000
UART5.DMADisableonRxErrorParam=UART_ADVFEATURE_DMA_DISABLEONRXERROR
UART5.Mode=MODE_RX
UART5.Parity=PARITY_EVEN
UART5.WordLength=WORDLENGTH_9B
UART7.BaudRate=921600
UART8.BaudRate=115200
UART9.BaudRate=921600
USART1.BaudRate=921600
USART1.VirtualMode-Asynchronous=VM_ASYNC
USART10.BaudRate=921600
USART10.VirtualMode=VM_ASYNC
USART2.BaudRate=921600
USART2.VirtualMode-Asynchronous=VM_ASYNC
USART2.VirtualMode-Hardware\ Flow\ Control\ (RS485)=VM_ASYNC
USART3.BaudRate=921600
USART3.VirtualMode-Asynchronous=VM_ASYNC
USART3.VirtualMode-Hardware\ Flow\ Control\ (RS485)=VM_ASYNC
USB_DEVICE.CLASS_NAME_HS=CDC
USB_DEVICE.VirtualMode=Cdc
USB_DEVICE.VirtualModeHS=Cdc_HS
USB_OTG_HS.VirtualMode-Device_Only_FS=Device_Only_FS
VP_FREERTOS_VS_CMSIS_V1.Mode=CMSIS_V1
VP_OCTOSPI2_VS_quad.Mode=quad_mode
VP_STMicroelectronics.X-CUBE-ALGOBUILD_VS_DSPOoLibraryJjLibrary_1.4.0_1.4.0.Mode=DSPOoLibraryJjLibrary
VP_SYS_VS_tim23.Mode=TIM23
VP_USB_DEVICE_VS_USB_DEVICE_CDC_HS.Mode=CDC_HS
board=custom

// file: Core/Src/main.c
/* USER CODE BEGIN Header */
/**
  ******************************************************************************
  * @file           : main.c
  * @brief          : Main program body
  ******************************************************************************
  * @attention
  *
  * Copyright (c) 2024 STMicroelectronics.
  * All rights reserved.
  *
  * This software is licensed under terms that can be found in the LICENSE file
  * in the root directory of this software component.
  * If no LICENSE file comes with this software, it is provided AS-IS.
  *
  ******************************************************************************
  */
/* USER CODE END Header */
#include "main.h"
#include "cmsis_os.h"
#include "adc.h"
#include "dma.h"
#include "fdcan.h"
#include "i2c.h"
#include "octospi.h"
#include "spi.h"
#include "tim.h"
#include "usart.h"
#include "usb_device.h"
#include "gpio.h"

/* USER CODE BEGIN Includes */
#include "robot.h"
#include "bsp_log.h"
/* USER CODE END Includes */

/* USER CODE BEGIN PV */
#define W25Qxx_NumByteToTest   	32*1024					// �������ݵĳ��ȣ�32K

int32_t OSPI_Status ; 		 //����־λ

uint8_t  W25Qxx_WriteBuffer[W25Qxx_NumByteToTest];		//	д��������
uint8_t  W25Qxx_ReadBuffer[W25Qxx_NumByteToTest];		//	����������
/* USER CODE END PV */

void SystemClock_Config(void);
void MX_FREERTOS_Init(void);

int main(void)
{

  /* MCU Configuration--------------------------------------------------------*/

  /* Reset of all peripherals, Initializes the Flash interface and the Systick. */
  HAL_Init();

  /* Configure the system clock */
  SystemClock_Config();

  /* Initialize all configured peripherals */
  MX_GPIO_Init();
  MX_DMA_Init();
  MX_ADC1_Init();
  MX_TIM12_Init();
  MX_SPI1_Init();
  MX_SPI2_Init();
  MX_TIM3_Init();
  MX_USART1_UART_Init();
  MX_USART2_UART_Init();
  MX_USART3_UART_Init();
  MX_UART7_Init();
  MX_USART10_UART_Init();
  MX_FDCAN1_Init();
  MX_FDCAN2_Init();
  MX_FDCAN3_Init();
  MX_TIM1_Init();
  MX_TIM2_Init();
  MX_OCTOSPI2_Init();
  MX_UART5_Init();
  MX_UART8_Init();
  MX_UART9_Init();
  MX_I2C2_Init();
  /* USER CODE BEGIN 2 */
  HAL_Delay(2000);
  RobotInit(); // Ψһ�ĳ�ʼ������
  LOGINFO("[main] SystemInit() and RobotInit() done");
  /* USER CODE END 2 */

  /* Call init function for freertos objects (in freertos.c) */
  MX_FREERTOS_Init();

  /* Start scheduler */
  osKernelStart();

  /* We should never get here as control is now taken by the scheduler */
  /* Infinite loop */
  /* USER CODE BEGIN WHILE */
  while (1)
  {
//	  vofa_start();

    /* USER CODE END WHILE */

  }
}

void SystemClock_Config(void)
{
  RCC_OscInitTypeDef RCC_OscInitStruct = {0};
  RCC_ClkInitTypeDef RCC_ClkInitStruct = {0};

  /** Supply configuration update enable
  */
  HAL_PWREx_ConfigSupply(PWR_LDO_SUPPLY);

  /** Configure the main internal regulator output voltage
  */
  __HAL_PWR_VOLTAGESCALING_CONFIG(PWR_REGULATOR_VOLTAGE_SCALE0);

  while(!__HAL_PWR_GET_FLAG(PWR_FLAG_VOSRDY)) {}

  /** Initializes the RCC Oscillators according to the specified parameters
  * in the RCC_OscInitTypeDef structure.
  */
  RCC_OscInitStruct.OscillatorType = RCC_OSCILLATORTYPE_HSI48|RCC_OSCILLATORTYPE_HSI
                              |RCC_OSCILLATORTYPE_HSE;
  RCC_OscInitStruct.HSEState = RCC_HSE_ON;
  RCC_OscInitStruct.HSIState = RCC_HSI_DIV1;
  RCC_OscInitStruct.HSICalibrationValue = 64;
  RCC_OscInitStruct.HSI48State = RCC_HSI48_ON;
  RCC_OscInitStruct.PLL.PLLState = RCC_PLL_ON;
  RCC_OscInitStruct.PLL.PLLSource = RCC_PLLSOURCE_HSE;
  RCC_OscInitStruct.PLL.PLLM = 2;
  RCC_OscInitStruct.PLL.PLLN = 40;
  RCC_OscInitStruct.PLL.PLLP = 1;
  RCC_OscInitStruct.PLL.PLLQ = 4;
  RCC_OscInitStruct.PLL.PLLR = 2;
  RCC_OscInitStruct.PLL.PLLRGE = RCC_PLL1VCIRANGE_3;
  RCC_OscInitStruct.PLL.PLLVCOSEL = RCC_PLL1VCOWIDE;
  RCC_OscInitStruct.PLL.PLLFRACN = 0;
  if (HAL_RCC_OscConfig(&RCC_OscInitStruct) != HAL_OK)
  {
    Error_Handler();
  }

  /** Initializes the CPU, AHB and APB buses clocks
  */
  RCC_ClkInitStruct.ClockType = RCC_CLOCKTYPE_HCLK|RCC_CLOCKTYPE_SYSCLK
                              |RCC_CLOCKTYPE_PCLK1|RCC_CLOCKTYPE_PCLK2
                              |RCC_CLOCKTYPE_D3PCLK1|RCC_CLOCKTYPE_D1PCLK1;
  RCC_ClkInitStruct.SYSCLKSource = RCC_SYSCLKSOURCE_PLLCLK;
  RCC_ClkInitStruct.SYSCLKDivider = RCC_SYSCLK_DIV1;
  RCC_ClkInitStruct.AHBCLKDivider = RCC_HCLK_DIV2;
  RCC_ClkInitStruct.APB3CLKDivider = RCC_APB3_DIV2;
  RCC_ClkInitStruct.APB1CLKDivider = RCC_APB1_DIV2;
  RCC_ClkInitStruct.APB2CLKDivider = RCC_APB2_DIV2;
  RCC_ClkInitStruct.APB4CLKDivider = RCC_APB4_DIV2;

  if (HAL_RCC_ClockConfig(&RCC_ClkInitStruct, FLASH_LATENCY_3) != HAL_OK)
  {
    Error_Handler();
  }
  HAL_RCC_MCOConfig(RCC_MCO1, RCC_MCO1SOURCE_HSI, RCC_MCODIV_1);
}

void HAL_TIM_PeriodElapsedCallback(TIM_HandleTypeDef *htim)
{
  if (htim->Instance == TIM23) {
    HAL_IncTick();
  }
}

void Error_Handler(void)
{
  __disable_irq();
  while (1)
  {
  }
}

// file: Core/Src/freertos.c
/* USER CODE BEGIN Header */
/**
  ******************************************************************************
  * File Name          : freertos.c
  * Description        : Code for freertos applications
  ******************************************************************************
  * @attention
  *
  * Copyright (c) 2024 STMicroelectronics.
  * All rights reserved.
  *
  * This software is licensed under terms that can be found in the LICENSE file
  * in the root directory of this software component.
  * If no LICENSE file comes with this software, it is provided AS-IS.
  *
  ******************************************************************************
  */
/* USER CODE END Header */

#include "FreeRTOS.h"
#include "task.h"
#include "main.h"
#include "cmsis_os.h"

osThreadId defaultTaskHandle;

void StartDefaultTask(void const * argument);

extern void MX_USB_DEVICE_Init(void);
void MX_FREERTOS_Init(void); /* (MISRA C 2004 rule 8.1) */

/* GetIdleTaskMemory prototype (linked to static allocation support) */
void vApplicationGetIdleTaskMemory( StaticTask_t **ppxIdleTaskTCBBuffer, StackType_t **ppxIdleTaskStackBuffer, uint32_t *pulIdleTaskStackSize );

/* GetTimerTaskMemory prototype (linked to static allocation support) */
void vApplicationGetTimerTaskMemory( StaticTask_t **ppxTimerTaskTCBBuffer, StackType_t **ppxTimerTaskStackBuffer, uint32_t *pulTimerTaskStackSize );

/* Hook prototypes */
void configureTimerForRunTimeStats(void);
unsigned long getRunTimeCounterValue(void);

/* USER CODE BEGIN 1 */
/* Functions needed when configGENERATE_RUN_TIME_STATS is on */
__weak void configureTimerForRunTimeStats(void)
{

}

__weak unsigned long getRunTimeCounterValue(void)
{
return 0;
}
/* USER CODE END 1 */

/* USER CODE BEGIN GET_IDLE_TASK_MEMORY */
static StaticTask_t xIdleTaskTCBBuffer;
static StackType_t xIdleStack[configMINIMAL_STACK_SIZE];

void vApplicationGetIdleTaskMemory( StaticTask_t **ppxIdleTaskTCBBuffer, StackType_t **ppxIdleTaskStackBuffer, uint32_t *pulIdleTaskStackSize )
{
  *ppxIdleTaskTCBBuffer = &xIdleTaskTCBBuffer;
  *ppxIdleTaskStackBuffer = &xIdleStack[0];
  *pulIdleTaskStackSize = configMINIMAL_STACK_SIZE;
  /* place for user code */
}
/* USER CODE END GET_IDLE_TASK_MEMORY */

/* USER CODE BEGIN GET_TIMER_TASK_MEMORY */
static StaticTask_t xTimerTaskTCBBuffer;
static StackType_t xTimerStack[configTIMER_TASK_STACK_DEPTH];

void vApplicationGetTimerTaskMemory( StaticTask_t **ppxTimerTaskTCBBuffer, StackType_t **ppxTimerTaskStackBuffer, uint32_t *pulTimerTaskStackSize )
{
  *ppxTimerTaskTCBBuffer = &xTimerTaskTCBBuffer;
  *ppxTimerTaskStackBuffer = &xTimerStack[0];
  *pulTimerTaskStackSize = configTIMER_TASK_STACK_DEPTH;
  /* place for user code */
}
/* USER CODE END GET_TIMER_TASK_MEMORY */

void MX_FREERTOS_Init(void) {

  /* Create the thread(s) */
  /* definition and creation of defaultTask */
  osThreadDef(defaultTask, StartDefaultTask, osPriorityNormal, 0, 128);
  defaultTaskHandle = osThreadCreate(osThread(defaultTask), NULL);

}

void StartDefaultTask(void const * argument)
{
  /* init code for USB_DEVICE */
  MX_USB_DEVICE_Init();
  for(;;)
  {
    osDelay(1);
  }
}
